# STM32F765BGT6 register map
File version: 1.0
Registers are 32-bit, access not given, reset 0x0 unless marked. A register's access mark holds for its fields unless they carry their own. Offsets are from the block's base; [hi:lo] are bit positions; {n}, {i} and the like mark numbered series; 'fields as' and 'values as' point back to an identical list.

## RCC
Base 0x40023800
0x00 CR
  [29] PLLSAIRDY, [28] PLLSAION, [27] PLLI2SRDY, [26] PLLI2SON, [25] PLLRDY, [24] PLLON, [31:20] s, [19] CSSON, [18] HSEBYP, [17] HSERDY, [16] HSEON, [n+8] HSICAL{n} (n=0..7), [n+3] HSITRIM{n} (n=0..4), [1] HSIRDY, [0] HSION
0x04 PLLCFGR
  [30] PLLR2, [29] PLLR1, [28] PLLR0, [n+24] PLLQ{n} (n=0..3), [22] PLLSRC, [17] PLLP1, [16] PLLP0, [31:15] s, [n+6] PLLN{n} (n=0..8), [n] PLLM{n} (n=0..5)
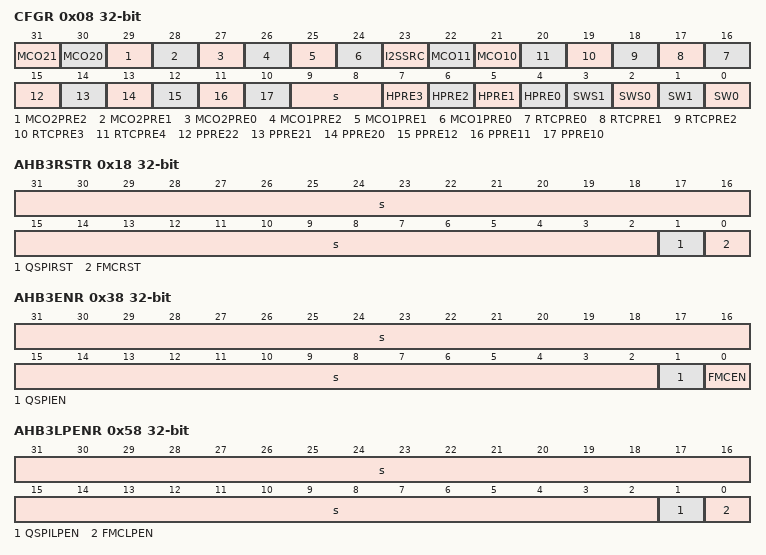
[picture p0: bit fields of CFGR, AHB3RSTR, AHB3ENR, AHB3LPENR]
0x08 CFGR
  [31] MCO21, [30] MCO20, [29] MCO2PRE2, [28] MCO2PRE1, [27] MCO2PRE0, [26] MCO1PRE2, [25] MCO1PRE1, [24] MCO1PRE0, [23] I2SSRC, [22] MCO11, [21] MCO10, [n+16] RTCPRE{n} (n=0..4), [15] PPRE22, [14] PPRE21, [13] PPRE20, [12] PPRE12, [11] PPRE11, [10] PPRE10, [9:8] s, [n+4] HPRE{n} (n=0..3), [3] SWS1, [2] SWS0, [1] SW1, [0] SW0
0x0C CIR
  [23] CSSC, [22] PLLSAIRDYC, [21] PLLI2SRDYC, [20] PLLRDYC, [19] HSERDYC, [18] HSIRDYC, [17] LSERDYC, [16] LSIRDYC, [31:15] s, [14] PLLSAIRDYIE, [13] PLLI2SRDYIE, [12] PLLRDYIE, [11] HSERDYIE, [10] HSIRDYIE, [9] LSERDYIE, [8] LSIRDYIE, [7] CSSF, [6] PLLSAIRDYF, [5] PLLI2SRDYF, [4] PLLRDYF, [3] HSERDYF, [2] HSIRDYF, [1] LSERDYF, [0] LSIRDYF
0x10 AHB1RSTR
  [29] OTGHSRST, [25] ETHMACRST, [23] DMA2DRST, [22] DMA2RST, [21] DMA1RST, [12] CRCRST, [31:11] s, [10] GPIOKRST, [9] GPIOJRST, [8] GPIOIRST, [7] GPIOHRST, [6] GPIOGRST, [5] GPIOFRST, [4] GPIOERST, [3] GPIODRST, [2] GPIOCRST, [1] GPIOBRST, [0] GPIOARST
0x14 AHB2RSTR
  [7] OTGFSRS, [6] RNGRST, [5] HASHRST, [4] CRYPRST, [31:2] s, [1] JPEGRST, [0] DCMIRST
0x18 AHB3RSTR
  [31:2] s, [1] QSPIRST, [0] FMCRST
0x20 APB1RSTR
  [31] UART8RST, [30] UART7RST, [29] DACRST, [28] PWRRST, [27] CECRST, [26] CAN2RST, [25] CAN1RST, [n+20] I2C{n}RST (n=1..4), [n+15] UART{n}RST (n=2..5), [16] SPDIFRXRST, [15] SPI3RST, [14] SPI2RST, [13] CAN3RST, [11] WWDGRST, [12:10] s, [9] LPTIM1RST, [8] TIM14RST, [7] TIM13RST, [6] TIM12RST, [n-2] TIM{n}RST (n=2..7)
0x24 APB2RSTR
  [30] MDIORST, [29] DFSDM1RST, [27] DSIRST, [26] LTDCRST, [23] SAI2RST, [22] SAI1RST, [21] SPI6RST, [20] SPI5RST, [18] TIM11RST, [17] TIM10RST, [16] TIM9RST, [14] SYSCFGRST, [13] SP45RST, [12] SPI1RST, [11] SDMMC1RST, [8] ADCRST, [7] SDMMC2RST, [5] USART6RST, [4] USART1RST, [31:2] s, [1] TIM8RST, [0] TIM1RST
0x30 AHB1ENR
  [30] OTGHSULPIEN, [29] OTGHSEN, [28] ETHMACPTPEN, [27] ETHMACRXEN, [26] ETHMACTXEN, [25] ETHMACEN, [23] DMA2DEN, [22] DMA2EN, [21] DMA1EN, [20] DTCMRAMEN, [18] BKPSRAMEN, [12] CRCEN, [31:11] s, [10] GPIOKEN, [9] GPIOJEN, [8] GPIOIEN, [7] GPIOHEN, [6] GPIOGEN, [5] GPIOFEN, [4] GPIOEEN, [3] GPIODEN, [2] GPIOCEN, [1] GPIOBEN, [0] GPIOAEN
0x34 AHB2ENR
  [7] OTGFSEN, [6] RNGEN, [5] HASHEN, [4] CRYPEN, [31:2] s, [1] JPEGEN, [0] DCMIEN
0x38 AHB3ENR
  [31:2] s, [1] QSPIEN, [0] FMCEN
0x40 APB1ENR
  [31] SPI8EN, [30] SPI7EN, [29] DACEN, [28] PWREN, [27] CECEN, [26] CAN2EN, [25] CAN1EN, [n+20] I2C{n}EN (n=1..4), [20] UART5EN, [19] UART4EN, [18] USART3EN, [17] USART2EN, [16] SPDIFRXEN, [15] SPI3EN, [14] SPI2EN, [13] CAN3EN, [11] WWDGEN, [12:10] s, [9] LPTIM1EN, [8] TIM14EN, [7] TIM13EN, [6] TIM12EN, [n-2] TIM{n}EN (n=2..7)
0x44 APB2ENR
  [30] MDIOEN, [29] DFSDM1EN, [27] DSIEN, [26] LTDCEN, [23] SAI2EN, [22] SAI1EN, [21] SPI6EN, [20] SPI5EN, [18] TIM11EN, [17] TIM10EN, [16] TIM9EN, [14] SYSCFGEN, [13] SPI4EN, [12] SPI1EN, [11] SDMMC1EN, [10] ADC3EN, [9] ADC2EN, [8] ADC1EN, [7] SDMMC2EN, [5] USART6EN, [4] USART1EN, [31:2] s, [1] TIM8EN, [0] TIM1EN
0x50 AHB1LPENR
  [30] OTGHSULPILPEN, [29] OTGHSLPEN, [28] ETHMACPTPLPEN, [27] ETHMACRXLPEN, [26] ETHMACTXLPEN, [25] ETHMACLPEN, [23] DMA2DLPEN, [22] DMA2LPEN, [21] DMA1LPEN, [20] DTCMLPEN, [18] BKPSRAMLPEN, [17] SRAM2LPEN, [16] SRAM1LPEN, [15] FLITFLPEN, [13] AXILPEN, [12] CRCLPEN, [31:11] s, [10] GPIOKLPEN, [9] GPIOJLPEN, [8] GPIOILPEN, [7] GPIOHLPEN, [6] GPIOGLPEN, [5] GPIOFLPEN, [4] GPIOELPEN, [3] GPIODLPEN, [2] GPIOCLPEN, [1] GPIOBLPEN, [0] GPIOALPEN
0x54 AHB2LPENR
  [7] OTGFSLPEN, [6] RNGLPEN, [5] HASHLPEN, [4] CRYPLPEN, [31:2] s, [1] JPEGLPEN, [0] DCMILPEN
0x58 AHB3LPENR
  [31:2] s, [1] QSPILPEN, [0] FMCLPEN
0x60 APB1LPENR
  [31] UART8LPEN, [30] UART7LPEN, [29] DACLPEN, [28] PWRLPEN, [27] CECLPEN, [26] CAN2LPEN, [25] CAN1LPEN, [n+20] I2C{n}LPEN (n=1..4), [20] UART5LPEN, [19] UART4LPEN, [18] USART3LPEN, [17] USART2LPEN, [16] SPDIFRXLPEN, [15] SPI3LPEN, [14] SPI2LPEN, [13] CAN3LPEN, [11] WWDGLPEN, [12:10] s, [9] LPTIM1LPEN, [8] TIM14LPEN, [7] TIM13LPEN, [6] TIM12LPEN, [n-2] TIM{n}LPEN (n=2..7)
0x64 APB2LPENR
  [30] MDIOLPEN, [29] DFSDM1LPEN, [27] DSILPEN, [26] LTDCLPEN, [23] SAI2LPEN, [22] SAI1LPEN, [21] SPI6LPEN, [20] SPI5LPEN, [18] TIM11LPEN, [17] TIM10LPEN, [16] TIM9LPEN, [14] SYSCFGLPEN, [13] SPI4LPEN, [12] SPI1LPEN, [11] SDMMC1LPEN, [10] ADC3LPEN, [9] ADC2LPEN, [8] ADC1LPEN, [7] SDMMC2LPEN, [5] USART6LPEN, [4] USART1LPEN, [31:2] s, [1] TIM8LPEN, [0] TIM1LPEN
0x70 BDCR
  [16] BDRST, [15] RTCEN, [9] RTCSEL1, [8] RTCSEL0, [31:5] s, [4:3] LSEDRV, [2] LSEBYP, [1] LSERDY, [0] LSEON
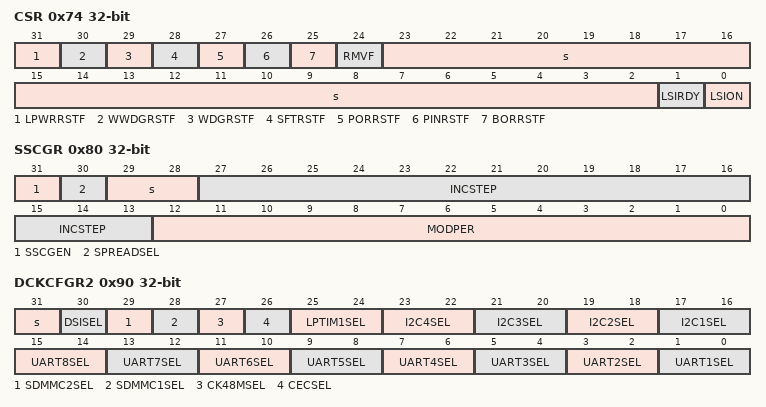
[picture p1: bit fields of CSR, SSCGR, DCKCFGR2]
0x74 CSR
  [31] LPWRRSTF, [30] WWDGRSTF, [29] WDGRSTF, [28] SFTRSTF, [27] PORRSTF, [26] PINRSTF, [25] BORRSTF, [24] RMVF, [23:2] s, [1] LSIRDY, [0] LSION
0x80 SSCGR
  [31] SSCGEN, [30] SPREADSEL, [29:28] s, [27:13] INCSTEP, [12:0] MODPER
0x84 PLLI2SCFGR
  [30:28] PLLI2SR, [27:24] PLLI2SQ, [17:16] PLLI2SP, [14:6] PLLI2SN, [31:0] s
0x88 PLLSAICFGR
  [30:28] PLLSAIR, [27:24] PLLSAIQ, [17:16] PLLSAIP, [14:6] PLLSAIN, [31:0] s
0x8C DCKCFGR1
  [26] ADFSDM1SEL, [25] DFSDM1SEL, [24] TIMPRE, [23:22] SAI2SEL, [21:20] SAI1SEL, [17:16] PLLSAIDIVR, [12:8] PLLSAIDIVQ, [31:5] s, [4:0] PLLI2SDIVQ
0x90 DCKCFGR2
  [31] s, [30] DSISEL, [29] SDMMC2SEL, [28] SDMMC1SEL, [27] CK48MSEL, [26] CECSEL, [25:24] LPTIM1SEL, [2n+15:2n+14] I2C{n}SEL (n=1..4), [2n-1:2n-2] UART{n}SEL (n=1..8)

## BKPSRAM
Base 0x40024000
Registers as RCC; these are added or differ:
0x30 AHB1ENR
  fields as RCC.AHB1ENR
0x50 AHB1LPENR
  fields as RCC.AHB1LPENR
